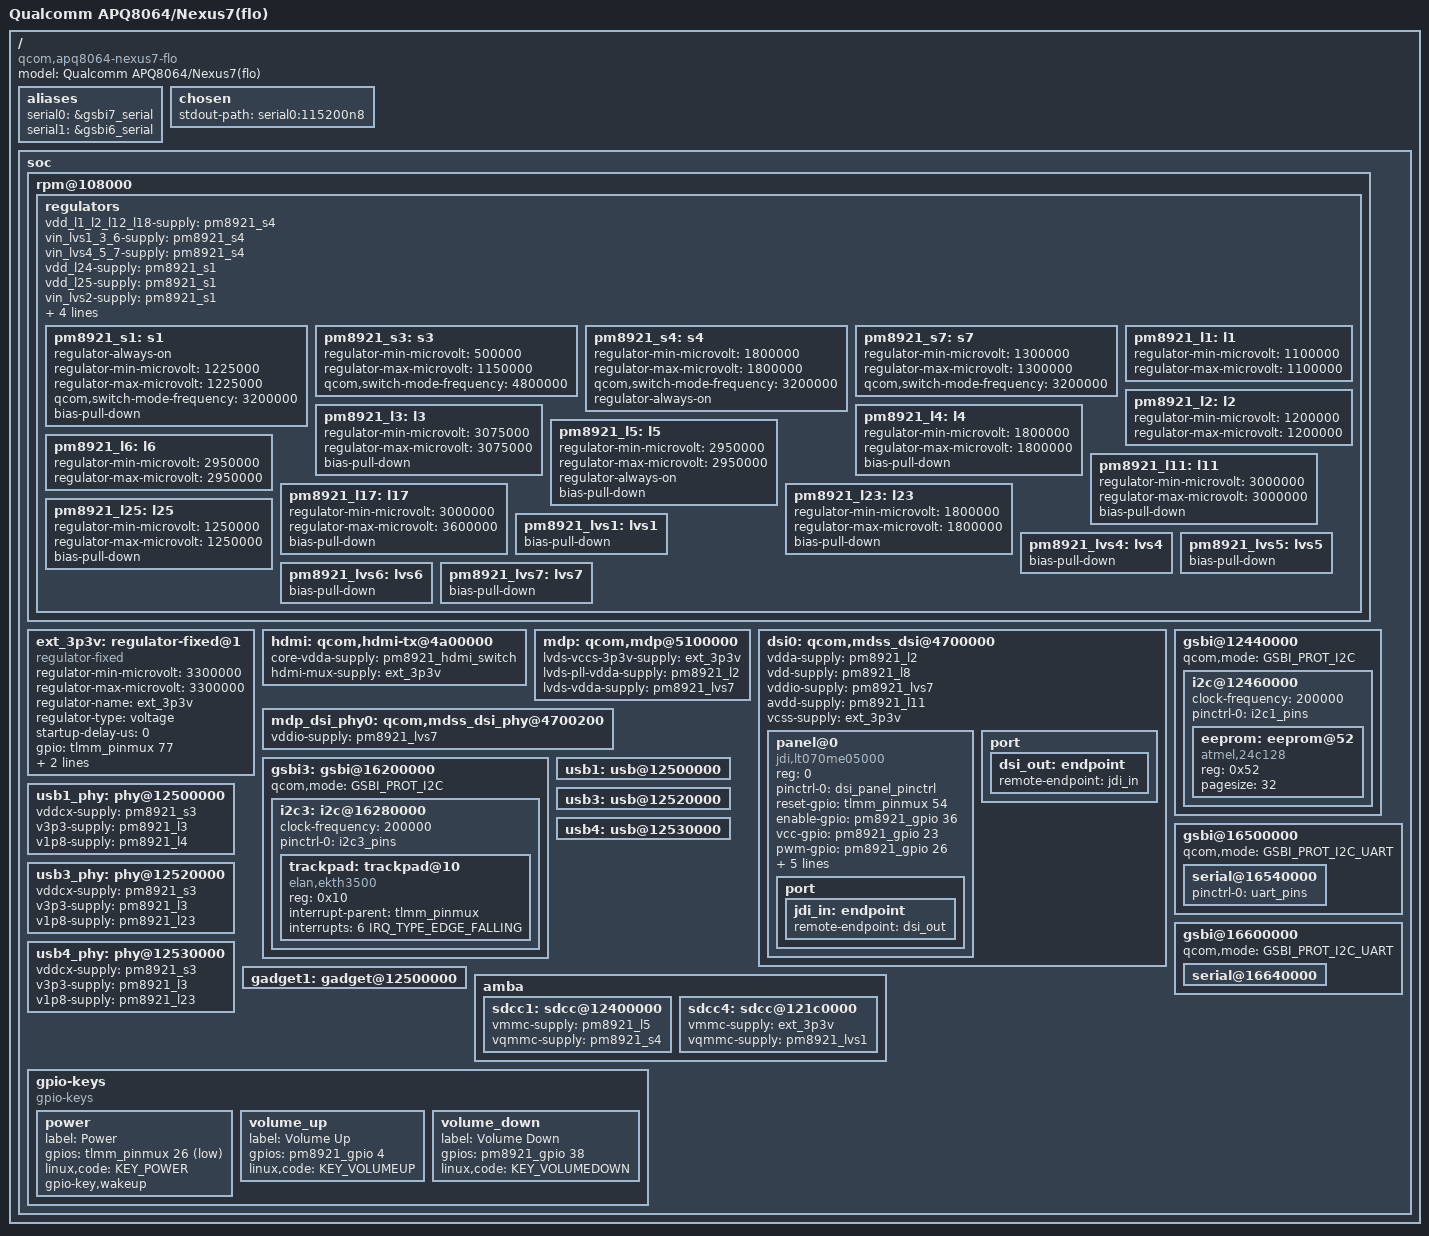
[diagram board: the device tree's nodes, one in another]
#include "qcom-apq8064-v2.0.dtsi"
#include <dt-bindings/gpio/gpio.h>
#include <dt-bindings/input/input.h>
#include <dt-bindings/pinctrl/qcom,pmic-gpio.h>
/ {
	model = "Qualcomm APQ8064/Nexus7(flo)";
	compatible = "qcom,apq8064-nexus7-flo", "qcom,apq8064";

	aliases {
		serial0 = &gsbi7_serial;
		serial1 = &gsbi6_serial;
	};

	chosen {
		stdout-path = "serial0:115200n8";
	};

	soc {
		rpm@108000 {
			regulators {
				vdd_l1_l2_l12_l18-supply = <&pm8921_s4>;
				vin_lvs1_3_6-supply = <&pm8921_s4>;
				vin_lvs4_5_7-supply = <&pm8921_s4>;


				vdd_l24-supply = <&pm8921_s1>;
				vdd_l25-supply = <&pm8921_s1>;
				vin_lvs2-supply = <&pm8921_s1>;

				vdd_l26-supply = <&pm8921_s7>;
				vdd_l27-supply = <&pm8921_s7>;
				vdd_l28-supply = <&pm8921_s7>;

				vdd_ncp-supply = <&pm8921_l6>;

				/* Buck SMPS */
				pm8921_s1: s1 {
					regulator-always-on;
					regulator-min-microvolt = <1225000>;
					regulator-max-microvolt = <1225000>;
					qcom,switch-mode-frequency = <3200000>;
					bias-pull-down;
				};

				/* msm otg HSUSB_VDDCX */
				pm8921_s3: s3 {
					regulator-min-microvolt = <500000>;
					regulator-max-microvolt = <1150000>;
					qcom,switch-mode-frequency = <4800000>;
				};

				/*
				 * msm_sdcc.1-sdc-vdd_io
				 * tabla2x-slim-CDC_VDDA_RX
				 * tabla2x-slim-CDC_VDDA_TX
				 * tabla2x-slim-CDC_VDD_CP
				 * tabla2x-slim-VDDIO_CDC
				 */
				pm8921_s4: s4 {
					regulator-min-microvolt	= <1800000>;
					regulator-max-microvolt	= <1800000>;
					qcom,switch-mode-frequency = <3200000>;
					regulator-always-on;
				};

				pm8921_s7: s7 {
					regulator-min-microvolt = <1300000>;
					regulator-max-microvolt = <1300000>;
					qcom,switch-mode-frequency = <3200000>;
				};

				pm8921_l1: l1 {
					regulator-min-microvolt = <1100000>;
					regulator-max-microvolt = <1100000>;
				};

				/* mipi_dsi.1-dsi1_pll_vdda */
				pm8921_l2: l2 {
					regulator-min-microvolt = <1200000>;
					regulator-max-microvolt = <1200000>;
				};

				/* msm_otg-HSUSB_3p3 */
				pm8921_l3: l3 {
					regulator-min-microvolt = <3075000>;
					regulator-max-microvolt = <3075000>;
					bias-pull-down;
				};

				/* msm_otg-HSUSB_1p8 */
				pm8921_l4: l4 {
					regulator-min-microvolt = <1800000>;
					regulator-max-microvolt = <1800000>;
					bias-pull-down;
				};

				/* msm_sdcc.1-sdc_vdd */
				pm8921_l5: l5 {
					regulator-min-microvolt = <2950000>;
					regulator-max-microvolt = <2950000>;
					regulator-always-on;
					bias-pull-down;
				};

				pm8921_l6: l6 {
					regulator-min-microvolt = <2950000>;
					regulator-max-microvolt = <2950000>;
				};

				/* mipi_dsi.1-dsi1_avdd */
				pm8921_l11: l11 {
					regulator-min-microvolt = <3000000>;
					regulator-max-microvolt = <3000000>;
					bias-pull-down;
				};

				pm8921_l17: l17 {
					regulator-min-microvolt = <3000000>;
					regulator-max-microvolt = <3600000>;
					bias-pull-down;
				};

				/* XXX no users on this though? */
				pm8921_l23: l23 {
					regulator-min-microvolt = <1800000>;
					regulator-max-microvolt = <1800000>;
					bias-pull-down;
				};

				/*
				 * tabla2x-slim-CDC_VDDA_A_1P2V
				 * tabla2x-slim-VDDD_CDC_D
				 */
				pm8921_l25: l25 {
					regulator-min-microvolt = <1250000>;
					regulator-max-microvolt = <1250000>;
					bias-pull-down;
				};

				pm8921_lvs1: lvs1 {
					bias-pull-down;
				};

				pm8921_lvs4: lvs4 {
					bias-pull-down;
				};
				pm8921_lvs5: lvs5 {
					bias-pull-down;
				};
				pm8921_lvs6: lvs6 {
					bias-pull-down;
				};
				/*
				 * mipi_dsi.1-dsi1_vddio
				 * pil_riva-pll_vdd
				 */
				pm8921_lvs7: lvs7 {
					bias-pull-down;
				};
			};
		};

		ext_3p3v: regulator-fixed@1 {
			compatible = "regulator-fixed";
			regulator-min-microvolt = <3300000>;
			regulator-max-microvolt = <3300000>;
			regulator-name = "ext_3p3v";
			regulator-type = "voltage";
			startup-delay-us = <0>;
			gpio = <&tlmm_pinmux 77 GPIO_ACTIVE_HIGH>;
			enable-active-high;
			regulator-boot-on;
		};

		hdmi: qcom,hdmi-tx@4a00000 {
			status = "okay";
			core-vdda-supply = <&pm8921_hdmi_switch>;
			hdmi-mux-supply = <&ext_3p3v>;
		};

		mdp: qcom,mdp@5100000 {
			status = "okay";
			lvds-vccs-3p3v-supply = <&ext_3p3v>;
			lvds-pll-vdda-supply = <&pm8921_l2>;
			lvds-vdda-supply = <&pm8921_lvs7>;
		};

/*		backlight: backlight{
			pinctrl-0 = <&pwm_bl_gpios>;
			pinctrl-names = "default";
			compatible = "gpio-backlight";
			gpios = <&pm8921_gpio 26 GPIO_ACTIVE_HIGH>;
			default-on;
		};
*/
		dsi0: qcom,mdss_dsi@4700000 {
			status = "okay";
			vdda-supply = <&pm8921_l2>;/*VDD_MIPI1 to 4*/
			vdd-supply = <&pm8921_l8>;
			vddio-supply = <&pm8921_lvs7>;
			avdd-supply = <&pm8921_l11>;
			vcss-supply = <&ext_3p3v>;	

			panel@0 {
				reg = <0>;
				compatible = "jdi,lt070me05000";

				pinctrl-names = "default";
				pinctrl-0 = <&dsi_panel_pinctrl>;

				reset-gpio = <&tlmm_pinmux 54 0>;
				enable-gpio = <&pm8921_gpio 36 GPIO_ACTIVE_HIGH>;
				vcc-gpio = <&pm8921_gpio 23 GPIO_ACTIVE_HIGH>;

				pwm-gpio = <&pm8921_gpio 26 GPIO_ACTIVE_HIGH>;
				/* TODO: Update backlight stuff */
				power-supply = <&pm8921_lvs5>;
				/*backlight = <&backlight>;*/
				backlit-supply = <&pm8921_l17>;
				avdd-supply = <&pm8921_l11>;
				iovdd-supply = <&pm8921_s4>;
				lvs7-supply = <&pm8921_lvs7>;

				port {
					jdi_in: endpoint {
						remote-endpoint = <&dsi_out>;
					};
				};
			};

			port {
				dsi_out: endpoint {
					remote-endpoint = <&jdi_in>;
				};
			};
		};

		mdp_dsi_phy0: qcom,mdss_dsi_phy@4700200 {
			status = "okay";
			vddio-supply = <&pm8921_lvs7>;/*VDD_PLL2_1 to 7*/
		};

		gsbi3: gsbi@16200000 {
			status = "okay";
			qcom,mode = <GSBI_PROT_I2C>;
			i2c3: i2c@16280000 {
				status = "okay";
				clock-frequency = <200000>;
				pinctrl-0 = <&i2c3_pins>;
				pinctrl-names = "default";

				trackpad: trackpad@10 {
					compatible = "elan,ekth3500";
					reg = <0x10>;
					interrupt-parent = <&tlmm_pinmux>;
					interrupts = <6 IRQ_TYPE_EDGE_FALLING>;
				};
			};
		};


		gsbi@12440000 {
			status = "okay";
			qcom,mode = <GSBI_PROT_I2C>;

			i2c@12460000 {
				status = "okay";
				clock-frequency = <200000>;
				pinctrl-0 = <&i2c1_pins>;
				pinctrl-names = "default";

				eeprom: eeprom@52 {
					compatible = "atmel,24c128";
					reg = <0x52>;
					pagesize = <32>;
				};
			};
		};

		gsbi@16500000 {
			status = "ok";
			qcom,mode = <GSBI_PROT_I2C_UART>;

			serial@16540000 {
				status = "ok";

				pinctrl-names = "default";
				pinctrl-0 = <&uart_pins>;
			};
		};

		gsbi@16600000 {
			status = "ok";
			qcom,mode = <GSBI_PROT_I2C_UART>;
			serial@16640000 {
				status = "ok";
			};
		};

		/* OTG */
		usb1_phy: phy@12500000 {
			status		= "okay";
			vddcx-supply	= <&pm8921_s3>;
			v3p3-supply	= <&pm8921_l3>;
			v1p8-supply	= <&pm8921_l4>;
		};

		usb3_phy: phy@12520000 {
			status		= "okay";
			vddcx-supply	= <&pm8921_s3>;
			v3p3-supply	= <&pm8921_l3>;
			v1p8-supply	= <&pm8921_l23>;
		};

		usb4_phy: phy@12530000 {
			status		= "okay";
			vddcx-supply	= <&pm8921_s3>;
			v3p3-supply	= <&pm8921_l3>;
			v1p8-supply	= <&pm8921_l23>;
		};

		gadget1: gadget@12500000 {
			status = "okay";
		};

		/* OTG */
		usb1: usb@12500000 {
			status = "okay";
		};

		usb3: usb@12520000 {
			status = "okay";
		};

		usb4: usb@12530000 {
			status = "okay";
		};

		amba {
			/* eMMC */
			sdcc1: sdcc@12400000 {
				status = "okay";
				vmmc-supply = <&pm8921_l5>;
				vqmmc-supply = <&pm8921_s4>;
			};

			/* WLAN */
			sdcc4: sdcc@121c0000 {
				status = "okay";
				vmmc-supply = <&ext_3p3v>;
				vqmmc-supply = <&pm8921_lvs1>;
			};
		};

		gpio-keys {
			compatible = "gpio-keys";
			power {
				label = "Power";
				gpios = <&tlmm_pinmux 26 GPIO_ACTIVE_LOW>;
				linux,code = <KEY_POWER>;
				gpio-key,wakeup;
			};
			volume_up {
				label = "Volume Up";
				gpios = <&pm8921_gpio 4 GPIO_ACTIVE_HIGH>;
				linux,code = <KEY_VOLUMEUP>;
			};
			volume_down {
				label = "Volume Down";
				gpios = <&pm8921_gpio 38 GPIO_ACTIVE_HIGH>;
				linux,code = <KEY_VOLUMEDOWN>;
			};
		};

	};
};
